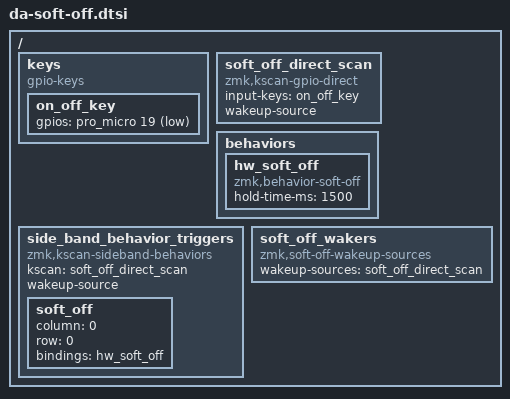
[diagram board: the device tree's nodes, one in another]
#include <dt-bindings/zmk/matrix_transform.h>

/ {
    keys {
        compatible = "gpio-keys";
        on_off_key: on_off_key {
            gpios = <&pro_micro 19 (GPIO_ACTIVE_LOW | GPIO_PULL_UP)>;
        };
    };

    soft_off_direct_scan: soft_off_direct_scan {
        compatible = "zmk,kscan-gpio-direct";
        input-keys = <&on_off_key>;
        wakeup-source;
    };

    behaviors {
        hw_soft_off: hw_soft_off {
            compatible = "zmk,behavior-soft-off";
            #binding-cells = <0>;
            hold-time-ms = <1500>;
        };
    };

    side_band_behavior_triggers: side_band_behavior_triggers {
        compatible = "zmk,kscan-sideband-behaviors";

        kscan = <&soft_off_direct_scan>;
        wakeup-source;

        soft_off {
            column = <0>;
            row = <0>;
            bindings = <&hw_soft_off>;
        };
    };

    soft_off_wakers {
        compatible = "zmk,soft-off-wakeup-sources";
        wakeup-sources = <&soft_off_direct_scan>;
    };
};
